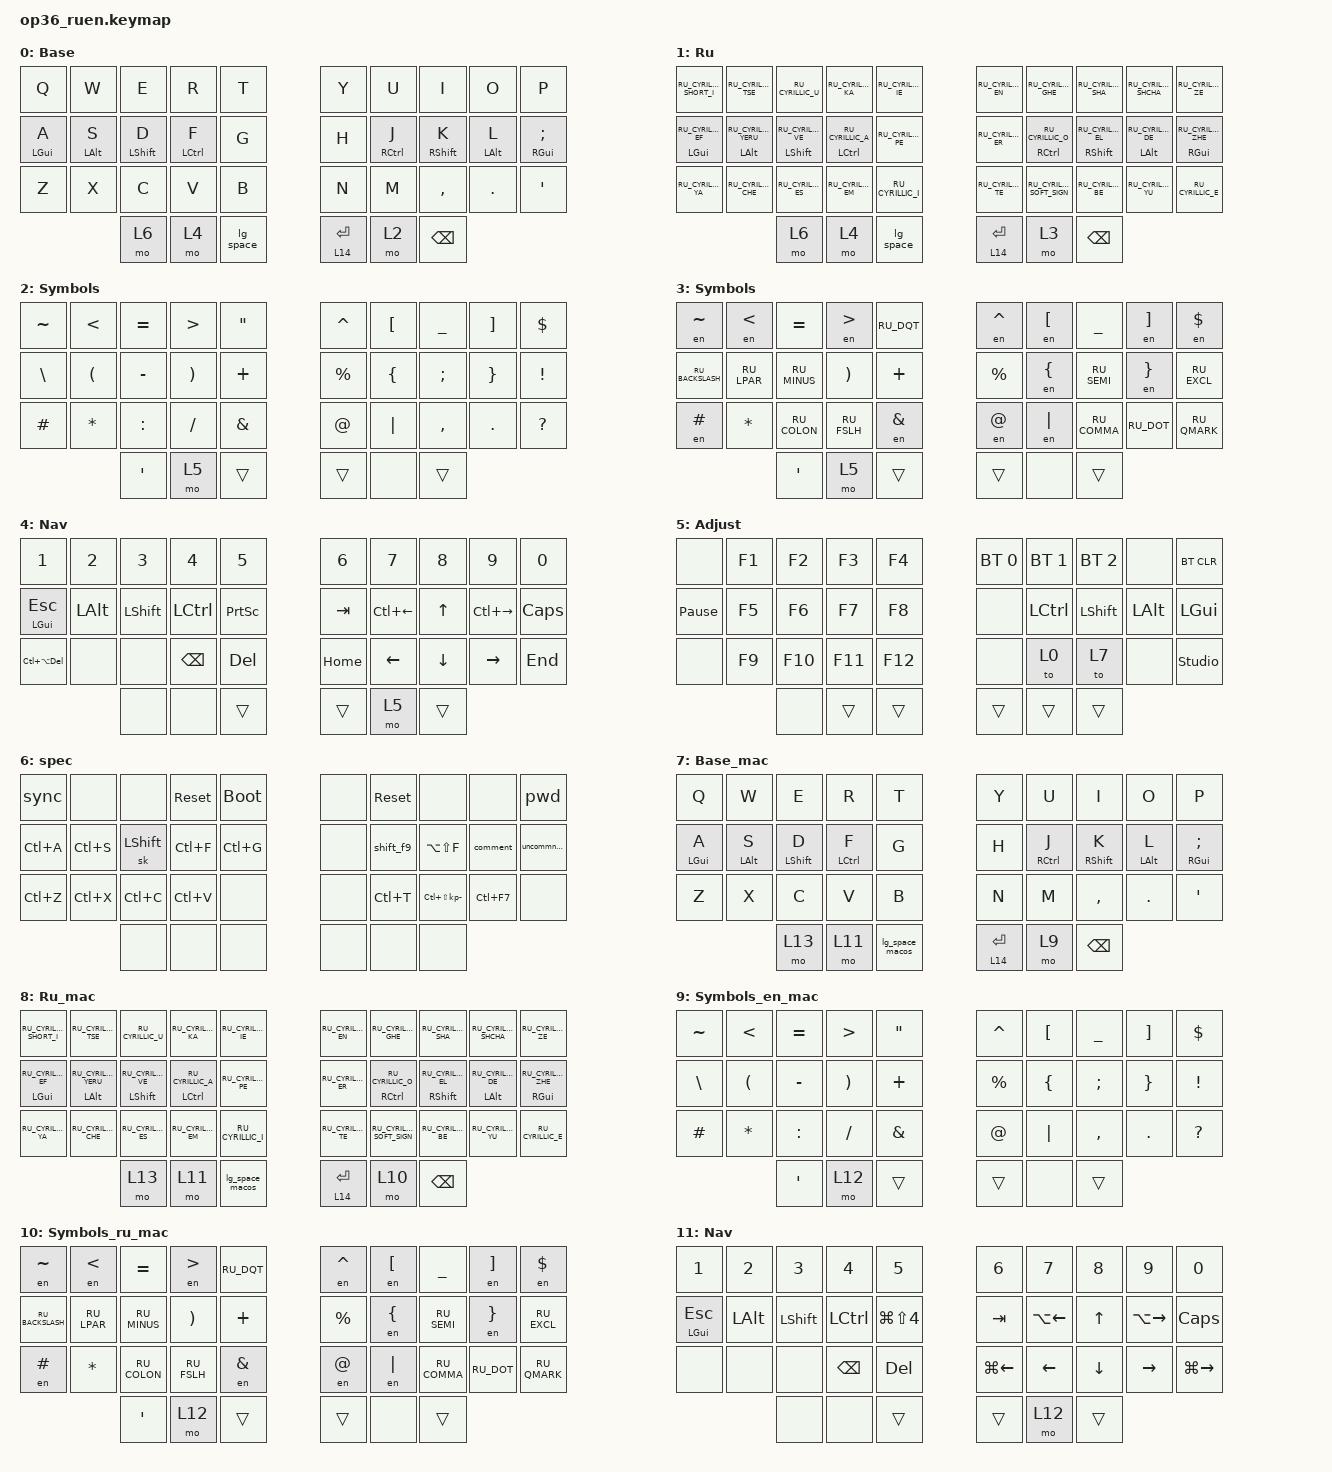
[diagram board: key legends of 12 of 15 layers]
#include "keys_ru.h"
#include "keys_ru.h"

#define ZMK_POINTING_DEFAULT_MOVE_VAL 2500
#define ZMK_POINTING_DEFAULT_SCRL_VAL 40

#include <behaviors.dtsi>
#include <dt-bindings/zmk/bt.h>
#include <dt-bindings/zmk/keys.h>
#include <dt-bindings/zmk/pointing.h>

&mt {
    quick-tap-ms = <200>;
    flavor = "tap-preferred";
    require-prior-idle-ms = <125>;
};

/ {
    behaviors {
        hml: home_row_mod_left {
            compatible = "zmk,behavior-hold-tap";
            #binding-cells = <2>;
            flavor = "balanced";
            require-prior-idle-ms = <150>;
            tapping-term-ms = <280>;
            quick-tap-ms = <175>;
            bindings = <&kp>, <&kp>;

            hold-trigger-key-positions = <5 6 7 8 9 15 16 17 18 19 25 26 27 28 29 33 34 35>;
            hold-trigger-on-release;
        };

        hmr: home_row_mod_right {
            compatible = "zmk,behavior-hold-tap";
            #binding-cells = <2>;
            flavor = "balanced";
            require-prior-idle-ms = <150>;
            tapping-term-ms = <280>;
            quick-tap-ms = <175>;
            bindings = <&kp>, <&kp>;

            hold-trigger-key-positions = <0 1 2 3 4 10 11 12 13 14 20 21 22 23 24 30 31 32>;
            hold-trigger-on-release;
        };

        lg_space: lg_space {
            compatible = "zmk,behavior-mod-morph";
            label = "toggle ru layer witch lgui";
            bindings = <&kp SPACE>, <&lg_tog>;

            #binding-cells = <0>;
            mods = <(MOD_LGUI)>;
        };

        lg_space_macos: lg_space_macos {
            compatible = "zmk,behavior-mod-morph";
            label = "LG_SPACE_MACOS";
            bindings = <&kp SPACE>, <&lg_tog_macos>;

            #binding-cells = <0>;
            mods = <(MOD_LGUI)>;
        };
    };

    combos {
        compatible = "zmk,combos";

        kha {
            bindings = <&kp RU_CYRILLIC_HA>;
            key-positions = <26 27>;
            layers = <1 8>;
        };

        hrdsgn {
            bindings = <&kp RU_CYRILLIC_HARD_SIGN>;
            key-positions = <27 28>;
            layers = <1 8>;
        };

        cmben {
            bindings = <&layer_en>;
            key-positions = <20 21>;
            layers = <1 8>;
        };

        cmbru {
            bindings = <&layer_ru>;
            key-positions = <28 29>;
            layers = <0 7>;
        };

        kavichki_en {
            bindings = <&kavichki_en>;
            key-positions = <13 12>;
            layers = <2 9>;
        };

        kavichki_ru {
            bindings = <&kavichki_ru>;
            key-positions = <13 12>;
            layers = <3 10>;
        };

        scobki_kavichki_en {
            bindings = <&scobki_kavichki_en>;
            key-positions = <22 23>;
            layers = <2 9>;
        };

        scobki_kavichki_ru {
            bindings = <&scobki_kavichki_ru>;
            key-positions = <22 23>;
            layers = <3 10>;
        };

        kvadro_skobki_kavichki_en {
            bindings = <&kvadro_skobki_kavichki_en>;
            key-positions = <2 3>;
            layers = <2 9>;
        };

        kvadro_skobki_kavichki_ru {
            bindings = <&kvadro_skobki_kavichki_ru>;
            key-positions = <2 3>;
            layers = <3 10>;
        };
    };

    macros {
        to_ru: to_ru {
            compatible = "zmk,behavior-macro";
            #binding-cells = <0>;
            bindings = <&kp LG(SPACE)>;
            label = "TO_RU";
            wait-ms = <5>;
            tap-ms = <5>;
        };

        to_en: to_en {
            compatible = "zmk,behavior-macro";
            #binding-cells = <0>;
            bindings = <&kp LG(SPACE)>;
            label = "TO_EN";
            wait-ms = <5>;
            tap-ms = <5>;
        };

        layer_en: layer_en {
            compatible = "zmk,behavior-macro";
            #binding-cells = <0>;
            bindings = <&to 0 &to_en>;
            label = "LAYER_EN";
            wait-ms = <5>;
            tap-ms = <5>;
        };

        layer_ru: layer_ru {
            compatible = "zmk,behavior-macro";
            #binding-cells = <0>;
            bindings = <&to 1 &to_ru>;
            label = "LAYER_RU";
            tap-ms = <5>;
            wait-ms = <5>;
        };

        en: en {
            compatible = "zmk,behavior-macro-one-param";
            #binding-cells = <1>;
            bindings =
                <&to_en>,
                <&macro_press>,
                <&macro_param_1to1 &kp MACRO_PLACEHOLDER>,
                <&macro_pause_for_release>,
                <&macro_release>,
                <&macro_param_1to1 &kp MACRO_PLACEHOLDER>,
                <&macro_tap>,
                <&to_ru>;

            label = "EN";
            wait-ms = <5>;
            tap-ms = <5>;
        };

        pwd: pwd {
            compatible = "zmk,behavior-macro";
            #binding-cells = <0>;
            bindings = <&none &kp T &kp N6 &kp X &kp N &kp J &kp Z &kp N3 &kp UNDER &kp EXCL &kp LS(D) &kp G &kp LS(D) &kp N4 &kp I &kp LS(N) &kp UNDER &kp G &kp D &kp G &kp LS(W) &kp LS(L) &kp UNDER &kp N &kp P &kp Z>;
            label = "PWD";
            tap-ms = <50>;
        };

        shift_f9: shift_f9 {
            compatible = "zmk,behavior-macro";
            #binding-cells = <0>;
            bindings = <&kp LS(F9)>;
            label = "SHIFT_F9";
            tap-ms = <40>;
        };

        lg_tog: lg_tog {
            compatible = "zmk,behavior-macro";
            #binding-cells = <0>;
            bindings = <&kp LG(SPACE) &tog 1>;
            label = "LG_TOG";
            tap-ms = <5>;
        };

        comment: comment1c {
            compatible = "zmk,behavior-macro";
            #binding-cells = <0>;
            bindings = <&kp LC(KP_DIVIDE)>;
            label = "COMMENT1C";
            tap-ms = <40>;
        };

        uncommnent: uncommnent1c {
            compatible = "zmk,behavior-macro";
            #binding-cells = <0>;
            bindings = <&kp LC(LS(KP_DIVIDE))>;
            label = "UNCOMMNENT1C";
            tap-ms = <40>;
        };

        sync: sync {
            compatible = "zmk,behavior-macro";
            #binding-cells = <0>;
            bindings = <&layer_ru &layer_ru>;
            label = "SYNC";
            wait-ms = <5>;
            tap-ms = <5>;
        };

        altfshift_f: altfshift_f {
            compatible = "zmk,behavior-macro";
            #binding-cells = <0>;
            bindings = <&kp LS(LA(F))>;
            label = "ALTFSHIFT_F";
            tap-ms = <40>;
        };

        scobki_kavichki_en: scobki {
            compatible = "zmk,behavior-macro";
            #binding-cells = <0>;
            bindings = <&kp LPAR &kp DQT &kp DQT &kp RPAR &kp LEFT_ARROW &kp LEFT_ARROW>;
            label = "SCOBKI";
        };

        kvadro_skobki_kavichki_en: kvadro_skobki {
            compatible = "zmk,behavior-macro";
            #binding-cells = <0>;
            bindings = <&kp LBKT &kp DQT &kp DQT &kp RBKT &kp LEFT_ARROW &kp LEFT_ARROW>;
            label = "KVADRO_SKOBKI";
        };

        kavichki_en: skobki_kavichki {
            compatible = "zmk,behavior-macro";
            #binding-cells = <0>;
            bindings = <&kp DQT &kp DQT &kp LEFT_ARROW>;
            label = "SKOBKI_KAVICHKI";
        };

        kavichki_ru: kavichki_ru {
            compatible = "zmk,behavior-macro";
            #binding-cells = <0>;
            bindings = <&to_en &kp DQT &kp DQT &kp LEFT_ARROW &to_ru>;
            label = "KAVICHKI_RU";
        };

        scobki_kavichki_ru: scobki_kavichki_ru {
            compatible = "zmk,behavior-macro";
            #binding-cells = <0>;
            bindings = <&to_en &kp LPAR &kp DQT &kp DQT &kp RPAR &kp LEFT_ARROW &kp LEFT_ARROW &to_ru>;
            label = "SCOBKI_KAVICHKI_RU";
        };

        kvadro_skobki_kavichki_ru: kvadro_skobki_kavichki_en {
            compatible = "zmk,behavior-macro";
            #binding-cells = <0>;
            bindings = <&to_en &kp LBKT &kp DQT &kp DQT &kp RBKT &kp LEFT_ARROW &kp LEFT_ARROW &to_ru>;
            label = "KVADRO_SKOBKI_KAVICHKI_EN";
        };

        int: int {
            compatible = "zmk,behavior-macro";
            #binding-cells = <0>;
            bindings = <&none &kp I &kp N &kp T &kp LPAR &kp I &kp N &kp P &kp U &kp T &kp LPAR &kp RPAR &kp RPAR>;
            label = "INT";
        };

        layer_en_macos: layer_en_macos {
            compatible = "zmk,behavior-macro";
            #binding-cells = <0>;
            bindings = <&to 7 &to_en>;
            label = "LAYER_EN_MACOS";
            wait-ms = <5>;
            tap-ms = <5>;
        };

        layer_ru_macos: layer_ru_macos {
            compatible = "zmk,behavior-macro";
            #binding-cells = <0>;
            bindings = <&to 8 &to_ru>;
            label = "LAYER_RU_MACOS";
            tap-ms = <5>;
            wait-ms = <5>;
        };

        lg_tog_macos: lg_tog_macos {
            compatible = "zmk,behavior-macro";
            #binding-cells = <0>;
            bindings = <&kp LG(SPACE) &tog 8>;
            label = "LG_TOG_MACOS";
            tap-ms = <5>;
            wait-ms = <5>;
        };

        sync_macos: sync_macos {
            compatible = "zmk,behavior-macro";
            #binding-cells = <0>;
            bindings = <&layer_ru_macos &layer_ru_macos>;
            label = "SYNC_MACOS";
            wait-ms = <5>;
            tap-ms = <5>;
        };
    };

    keymap {
        compatible = "zmk,keymap";

        en {
            bindings = <
  &kp Q        &kp W        &kp E         &kp R         &kp T                             &kp Y  &kp U          &kp I         &kp O        &kp P
  &hml LGUI A  &hml LALT S  &hml LSHFT D  &hml LCTRL F  &kp G                             &kp H  &hmr RCTRL J   &hmr RSHFT K  &hmr LALT L  &hmr RGUI SEMICOLON
  &kp Z        &kp X        &kp C         &kp V         &kp B                             &kp N  &kp M          &kp COMMA     &kp DOT      &kp SQT
                                          &mo 6         &mo 4  &lg_space    &lt 14 ENTER  &mo 2  &kp BACKSPACE
            >;

            display-name = "Base";
        };

        ru {
            bindings = <
  &kp RU_CYRILLIC_SHORT_I   &kp RU_CYRILLIC_TSE         &kp RU_CYRILLIC_U          &kp RU_CYRILLIC_KA        &kp RU_CYRILLIC_IE                             &kp RU_CYRILLIC_EN  &kp RU_CYRILLIC_GHE        &kp RU_CYRILLIC_SHA        &kp RU_CYRILLIC_SHCHA     &kp RU_CYRILLIC_ZE
  &hml LGUI RU_CYRILLIC_EF  &hml LALT RU_CYRILLIC_YERU  &hml LSHFT RU_CYRILLIC_VE  &hml LCTRL RU_CYRILLIC_A  &kp RU_CYRILLIC_PE                             &kp RU_CYRILLIC_ER  &hmr RCTRL RU_CYRILLIC_O   &hmr RSHFT RU_CYRILLIC_EL  &hmr LALT RU_CYRILLIC_DE  &hmr RGUI RU_CYRILLIC_ZHE
  &kp RU_CYRILLIC_YA        &kp RU_CYRILLIC_CHE         &kp RU_CYRILLIC_ES         &kp RU_CYRILLIC_EM        &kp RU_CYRILLIC_I                              &kp RU_CYRILLIC_TE  &kp RU_CYRILLIC_SOFT_SIGN  &kp RU_CYRILLIC_BE         &kp RU_CYRILLIC_YU        &kp RU_CYRILLIC_E
                                                                                   &mo 6                     &mo 4               &lg_space    &lt 14 ENTER  &mo 3               &kp BACKSPACE
            >;

            display-name = "Ru";
        };

        sym_en {
            bindings = <
  &kp TILDE  &kp LT    &kp EQUAL  &kp GT    &kp DQT                     &kp CARET  &kp LBKT  &kp UNDER  &kp RBKT  &kp DLLR
  &kp BSLH   &kp LPAR  &kp MINUS  &kp RPAR  &kp PLUS                    &kp PRCNT  &kp LBRC  &kp SEMI   &kp RBRC  &kp EXCL
  &kp HASH   &kp STAR  &kp COLON  &kp FSLH  &kp AMPS                    &kp AT     &kp PIPE  &kp COMMA  &kp DOT   &kp QMARK
                                  &kp SQT   &mo 5     &trans    &trans  &none      &trans
            >;

            display-name = "Symbols";
        };

        sym_ru {
            bindings = <
  &en TILDE         &en LT       &kp EQUAL     &en GT       &kp RU_DQT                    &en CARET  &en LBKT  &kp UNDER     &en RBKT    &en DLLR
  &kp RU_BACKSLASH  &kp RU_LPAR  &kp RU_MINUS  &kp RPAR     &kp PLUS                      &kp PRCNT  &en LBRC  &kp RU_SEMI   &en RBRC    &kp RU_EXCL
  &en HASH          &kp STAR     &kp RU_COLON  &kp RU_FSLH  &en AMPS                      &en AT     &en PIPE  &kp RU_COMMA  &kp RU_DOT  &kp RU_QMARK
                                               &kp SQT      &mo 5       &trans    &trans  &none      &trans
            >;

            display-name = "Symbols";
        };

        nav {
            bindings = <
  &kp N1           &kp N2    &kp N3     &kp N4         &kp N5                             &kp N6    &kp N7              &kp N8          &kp N9               &kp N0
  &hml LGUI ESC    &kp LALT  &kp LSHFT  &kp LCTRL      &kp PRINTSCREEN                    &kp TAB   &kp LC(LEFT_ARROW)  &kp UP_ARROW    &kp LC(RIGHT_ARROW)  &kp CAPSLOCK
  &kp LC(LA(DEL))  &none     &none      &kp BACKSPACE  &kp DELETE                         &kp HOME  &kp LEFT_ARROW      &kp DOWN_ARROW  &kp RIGHT_ARROW      &kp END
                                        &none          &none            &trans    &trans  &mo 5     &trans
            >;

            display-name = "Nav";
        };

        adj {
            bindings = <
  &none            &kp F1  &kp F2   &kp F3   &kp F4                     &bt BT_SEL 0  &bt BT_SEL 1  &bt BT_SEL 2  &none     &bt BT_CLR
  &kp PAUSE_BREAK  &kp F5  &kp F6   &kp F7   &kp F8                     &none         &kp LCTRL     &kp LSHIFT    &kp LALT  &kp LGUI
  &none            &kp F9  &kp F10  &kp F11  &kp F12                    &none         &to 0         &to 7         &none     &studio_unlock
                                    &none    &trans   &trans    &trans  &trans        &trans
            >;

            display-name = "Adjust";
        };

        spec {
            bindings = <
  &sync      &none      &none           &sys_reset  &bootloader                  &none  &sys_reset  &none                 &none       &pwd
  &kp LC(A)  &kp LC(S)  &sk LEFT_SHIFT  &kp LC(F)   &kp LC(G)                    &none  &shift_f9   &kp LA(LS(F))         &comment    &uncommnent
  &kp LC(Z)  &kp LC(X)  &kp LC(C)       &kp LC(V)   &none                        &none  &kp LC(T)   &kp LC(LS(KP_MINUS))  &kp LC(F7)  &none
                                        &none       &none        &none    &none  &none  &none
            >;
        };

        en_mac {
            display-name = "Base_mac";
            bindings = <
  &kp Q        &kp W        &kp E         &kp R         &kp T                                    &kp Y  &kp U          &kp I         &kp O        &kp P
  &hml LGUI A  &hml LALT S  &hml LSHFT D  &hml LCTRL F  &kp G                                    &kp H  &hmr RCTRL J   &hmr RSHFT K  &hmr LALT L  &hmr RGUI SEMICOLON
  &kp Z        &kp X        &kp C         &kp V         &kp B                                    &kp N  &kp M          &kp COMMA     &kp DOT      &kp SQT
                                          &mo 13        &mo 11  &lg_space_macos    &lt 14 ENTER  &mo 9  &kp BACKSPACE
            >;
        };

        ru_mac {
            display-name = "Ru_mac";
            bindings = <
  &kp RU_CYRILLIC_SHORT_I   &kp RU_CYRILLIC_TSE         &kp RU_CYRILLIC_U          &kp RU_CYRILLIC_KA        &kp RU_CYRILLIC_IE                                   &kp RU_CYRILLIC_EN  &kp RU_CYRILLIC_GHE        &kp RU_CYRILLIC_SHA        &kp RU_CYRILLIC_SHCHA     &kp RU_CYRILLIC_ZE
  &hml LGUI RU_CYRILLIC_EF  &hml LALT RU_CYRILLIC_YERU  &hml LSHFT RU_CYRILLIC_VE  &hml LCTRL RU_CYRILLIC_A  &kp RU_CYRILLIC_PE                                   &kp RU_CYRILLIC_ER  &hmr RCTRL RU_CYRILLIC_O   &hmr RSHFT RU_CYRILLIC_EL  &hmr LALT RU_CYRILLIC_DE  &hmr RGUI RU_CYRILLIC_ZHE
  &kp RU_CYRILLIC_YA        &kp RU_CYRILLIC_CHE         &kp RU_CYRILLIC_ES         &kp RU_CYRILLIC_EM        &kp RU_CYRILLIC_I                                    &kp RU_CYRILLIC_TE  &kp RU_CYRILLIC_SOFT_SIGN  &kp RU_CYRILLIC_BE         &kp RU_CYRILLIC_YU        &kp RU_CYRILLIC_E
                                                                                   &mo 13                    &mo 11              &lg_space_macos    &lt 14 ENTER  &mo 10              &kp BACKSPACE
            >;
        };

        sym_en_mac {
            display-name = "Symbols_en_mac";
            bindings = <
  &kp TILDE  &kp LT    &kp EQUAL  &kp GT    &kp DQT                     &kp CARET  &kp LBKT  &kp UNDER  &kp RBKT  &kp DLLR
  &kp BSLH   &kp LPAR  &kp MINUS  &kp RPAR  &kp PLUS                    &kp PRCNT  &kp LBRC  &kp SEMI   &kp RBRC  &kp EXCL
  &kp HASH   &kp STAR  &kp COLON  &kp FSLH  &kp AMPS                    &kp AT     &kp PIPE  &kp COMMA  &kp DOT   &kp QMARK
                                  &kp SQT   &mo 12    &trans    &trans  &none      &trans
            >;
        };

        sym_ru_mac {
            display-name = "Symbols_ru_mac";
            bindings = <
  &en TILDE         &en LT       &kp EQUAL     &en GT       &kp RU_DQT                    &en CARET  &en LBKT  &kp UNDER     &en RBKT    &en DLLR
  &kp RU_BACKSLASH  &kp RU_LPAR  &kp RU_MINUS  &kp RPAR     &kp PLUS                      &kp PRCNT  &en LBRC  &kp RU_SEMI   &en RBRC    &kp RU_EXCL
  &en HASH          &kp STAR     &kp RU_COLON  &kp RU_FSLH  &en AMPS                      &en AT     &en PIPE  &kp RU_COMMA  &kp RU_DOT  &kp RU_QMARK
                                               &kp SQT      &mo 12      &trans    &trans  &none      &trans
            >;
        };

        nav_mac {
            display-name = "Nav";
            bindings = <
  &kp N1         &kp N2    &kp N3     &kp N4         &kp N5                                  &kp N6              &kp N7              &kp N8          &kp N9               &kp N0
  &hml LGUI ESC  &kp LALT  &kp LSHFT  &kp LCTRL      &kp LG(LS(NUMBER_4))                    &kp TAB             &kp LA(LEFT_ARROW)  &kp UP_ARROW    &kp LA(RIGHT_ARROW)  &kp CAPSLOCK
  &none          &none     &none      &kp BACKSPACE  &kp DELETE                              &kp LG(LEFT_ARROW)  &kp LEFT_ARROW      &kp DOWN_ARROW  &kp RIGHT_ARROW      &kp LG(RIGHT_ARROW)
                                      &none          &none                 &trans    &trans  &mo 12              &trans
            >;
        };

        adj_mac {
            display-name = "Adjust";
            bindings = <
  &none            &kp F1  &kp F2   &kp F3   &kp F4                     &bt BT_SEL 0  &bt BT_SEL 1  &bt BT_SEL 2  &none     &bt BT_CLR
  &kp PAUSE_BREAK  &kp F5  &kp F6   &kp F7   &kp F8                     &none         &kp LCTRL     &kp LSHIFT    &kp LALT  &kp LGUI
  &none            &kp F9  &kp F10  &kp F11  &kp F12                    &none         &to 0         &to 7         &none     &studio_unlock
                                    &none    &trans   &trans    &trans  &trans        &trans
            >;
        };

        spec_mac {
            bindings = <
  &sync_macos  &none      &int       &none      &bootloader                  &none  &none  &none  &none  &none
  &kp LG(A)    &kp LG(S)  &none      &kp LG(F)  &kp LG(G)                    &none  &none  &none  &none  &none
  &kp LG(Z)    &kp LG(X)  &kp LG(C)  &kp LG(V)  &none                        &none  &none  &none  &none  &none
                                     &none      &none        &none    &none  &none  &none
            >;
        };

        layer_14 {
            bindings = <
  &trans  &trans  &trans  &trans  &trans                    &trans          &trans          &trans          &trans           &trans
  &trans  &trans  &trans  &trans  &trans                    &msc SCRL_UP    &mkp LCLK       &mmv MOVE_UP    &mkp RCLK        &trans
  &trans  &trans  &trans  &trans  &trans                    &msc SCRL_DOWN  &mmv MOVE_LEFT  &mmv MOVE_DOWN  &mmv MOVE_RIGHT  &trans
                          &trans  &trans  &trans    &trans  &trans          &trans
            >;
        };
    };
};
